# SWM330 register map
File version: 1.0
CPU: CM0 r1p0, little endian, 2 interrupt priority bits
Registers are 32-bit, read-write, no defined reset value unless marked. A register's access mark holds for its fields unless they carry their own. Offsets are from the block's base; [hi:lo] are bit positions; lines under a group give offsets from that group; {n}, {i} and the like mark numbered series; 'fields as' and 'values as' point back to an identical list.

## DMA2D — Registers group
Base 0x40003000
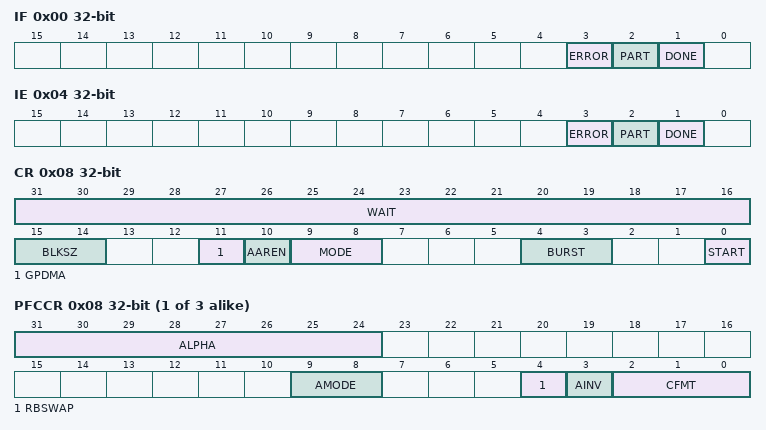
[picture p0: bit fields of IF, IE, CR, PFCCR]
0x00 IF
  [3] ERROR, [2] PART, [1] DONE
0x04 IE
  [3] ERROR, [2] PART, [1] DONE
0x08 CR
  [31:16] WAIT, [15:14] BLKSZ, [11] GPDMA, [10] AAREN, [9:8] MODE, [4:3] BURST, [0] START
{0x10+0x10*i} L{i} group (i=0..2) — register cluster
  0x00 MAR
  0x04 OR
  0x08 PFCCR
    [31:24] ALPHA, [9:8] AMODE, [4] RBSWAP, [3] AINV, [2:0] CFMT
  0x0C COLOR
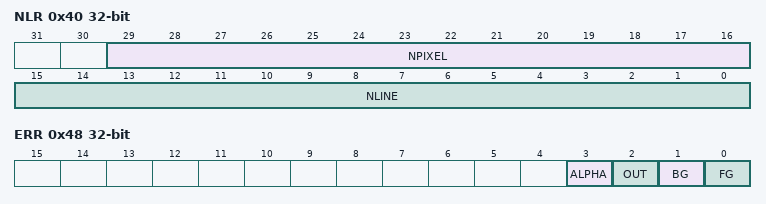
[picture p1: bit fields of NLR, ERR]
0x40 NLR
  [29:16] NPIXEL, [15:0] NLINE
0x44 AAR
0x48 ERR
  [3] ALPHA, [2] OUT, [1] BG, [0] FG

## JPEG — Registers group
Base 0x40004000
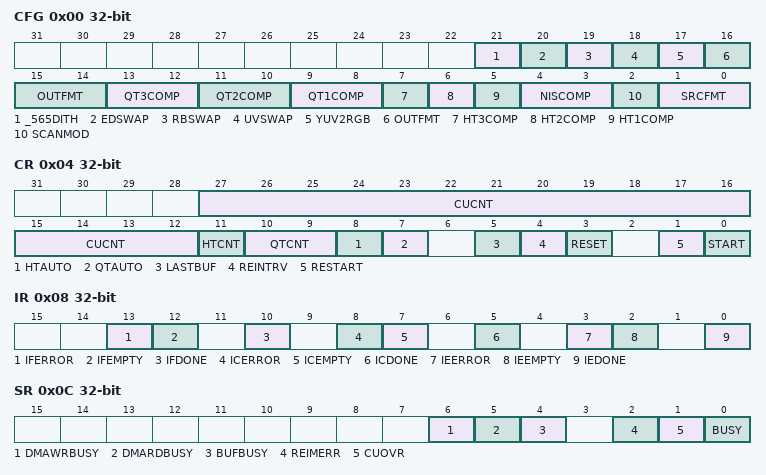
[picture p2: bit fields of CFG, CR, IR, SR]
0x00 CFG
  [21] _565DITH, [20] EDSWAP, [19] RBSWAP, [18] UVSWAP, [17] YUV2RGB, [16:14] OUTFMT, [13:12] QT3COMP, [11:10] QT2COMP, [9:8] QT1COMP, [7] HT3COMP, [6] HT2COMP, [5] HT1COMP, [4:3] NISCOMP, [2] SCANMOD, [1:0] SRCFMT
0x04 CR
  [27:12] CUCNT, [11] HTCNT, [10:9] QTCNT, [8] HTAUTO, [7] QTAUTO, [5] LASTBUF, [4] REINTRV, [3] RESET, [1] RESTART, [0] START
0x08 IR
  [13] IFERROR, [12] IFEMPTY, [10] IFDONE, [8] ICERROR, [7] ICEMPTY, [5] ICDONE, [3] IEERROR, [2] IEEMPTY, [0] IEDONE
0x0C SR
  [6] DMAWRBUSY, [5] DMARDBUSY, [4] BUFBUSY, [2] REIMERR, [1] CUOVR, [0] BUSY
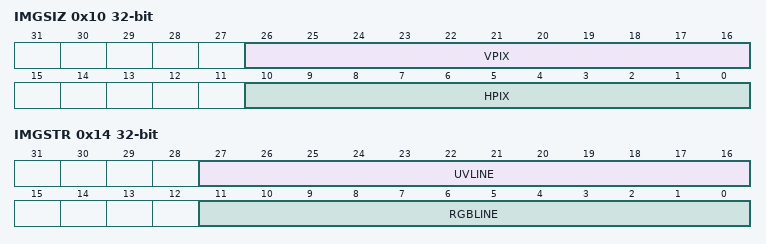
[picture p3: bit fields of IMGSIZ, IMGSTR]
0x10 IMGSIZ
  [26:16] VPIX, [10:0] HPIX
0x14 IMGSTR
  [27:16] UVLINE, [11:0] RGBLINE
0x18 CSBASE
0x1C YBASE
0x1C RGBASE (alternate view of YBASE)
0x20 UBASE
0x24 VBASE
0x28 QTBASE
0x2C HTBASE
0x30 CODLEN
{0x100+4i} QTABLE0_[{i}] (i=0..15) wo
{0x140+4i} QTABLE1_[{i}] (i=0..15) wo
{0x180+4i} QTABLE2_[{i}] (i=0..15) wo
0x200 HTABLE0 group — register cluster
  {0x0+4j} DC_CODEWORD[{j}] (j=0..5) wo
  {0x18+4j} DC_CODELEN[{j}] (j=0..1) wo
  {0x20+4j} DC_CODEVAL[{j}] (j=0..1) wo
  {0x28+4j} AC_CODEWORD[{j}] (j=0..7) wo
  {0x48+4j} AC_CODEADDR[{j}] (j=0..3) wo
  {0x58+4j} AC_CODEVAL[{j}] (j=0..40) wo
0x300 HTABLE1 group — register cluster
  {0x0+4j} DC_CODEWORD[{j}] (j=0..5) wo
  {0x18+4j} DC_CODELEN[{j}] (j=0..1) wo
  {0x20+4j} DC_CODEVAL[{j}] (j=0..1) wo
  {0x28+4j} AC_CODEWORD[{j}] (j=0..7) wo
  {0x48+4j} AC_CODEADDR[{j}] (j=0..3) wo
  {0x58+4j} AC_CODEVAL[{j}] (j=0..40) wo

## SRA — Registers group
Base 0x40002800
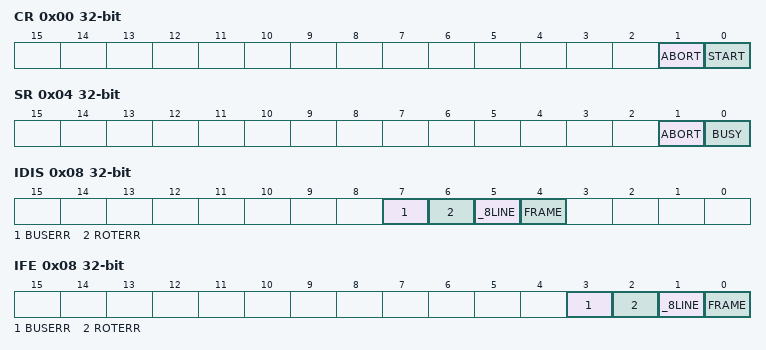
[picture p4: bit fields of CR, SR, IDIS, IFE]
0x00 CR wo
  [1] ABORT, [0] START
0x04 SR ro
  [1] ABORT, [0] BUSY
0x08 IDIS
  [7] BUSERR, [6] ROTERR, [5] _8LINE, [4] FRAME
0x08 IFE (alternate view of IDIS)
  [3] BUSERR, [2] ROTERR, [1] _8LINE, [0] FRAME
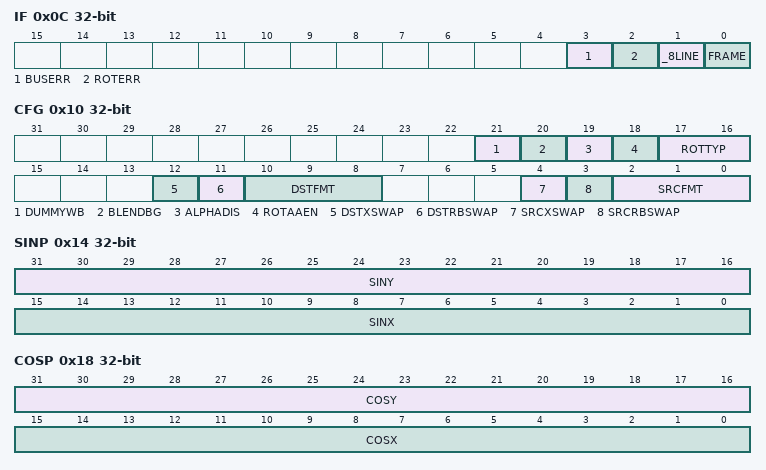
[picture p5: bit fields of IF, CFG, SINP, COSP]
0x0C IF
  [3] BUSERR, [2] ROTERR, [1] _8LINE, [0] FRAME
0x10 CFG
  [21] DUMMYWB, [20] BLENDBG, [19] ALPHADIS, [18] ROTAAEN, [17:16] ROTTYP, [12] DSTXSWAP, [11] DSTRBSWAP, [10:8] DSTFMT, [4] SRCXSWAP, [3] SRCRBSWAP, [2:0] SRCFMT
0x14 SINP
  [31:16] SINY, [15:0] SINX
0x18 COSP
  [31:16] COSY, [15:0] COSX
0x1C SRC_TILE_POSX
0x20 SRC_TILE_POSY
0x24 DST_TILE_OFFX
0x28 DST_TILE_OFFY
0x2C BGCOLOR
0x30 SRCBASE
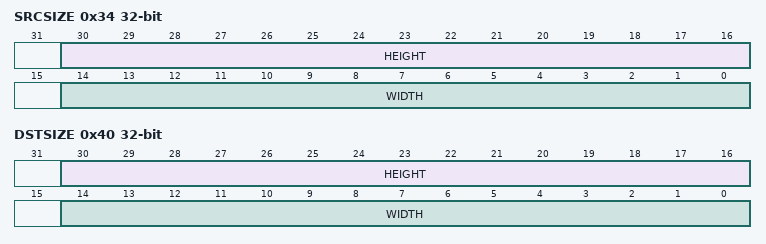
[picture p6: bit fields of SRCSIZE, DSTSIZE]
0x34 SRCSIZE
  [30:16] HEIGHT, [14:0] WIDTH
0x38 SRCSTRIDE
0x3C DSTBASE
0x40 DSTSIZE
  [30:16] HEIGHT, [14:0] WIDTH
0x44 DSTSTRIDE

## DVP — Registers group
Base 0x40003900
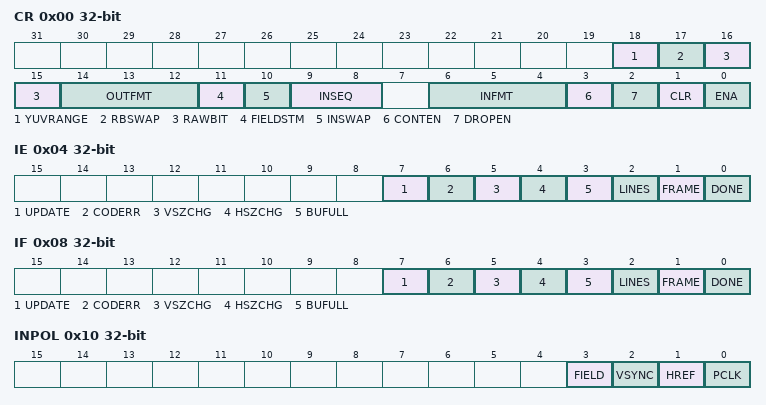
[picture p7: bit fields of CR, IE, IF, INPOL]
0x00 CR
  [18] YUVRANGE, [17] RBSWAP, [16:15] RAWBIT, [14:12] OUTFMT, [11] FIELDSTM, [10] INSWAP, [9:8] INSEQ, [6:4] INFMT, [3] CONTEN, [2] DROPEN, [1] CLR, [0] ENA
0x04 IE
  [7] UPDATE, [6] CODERR, [5] VSZCHG, [4] HSZCHG, [3] BUFULL, [2] LINES, [1] FRAME, [0] DONE
0x08 IF
  fields as IE
0x0C ICFG
  [30:16] LINES
0x10 INPOL
  [3] FIELD, [2] VSYNC, [1] HREF, [0] PCLK
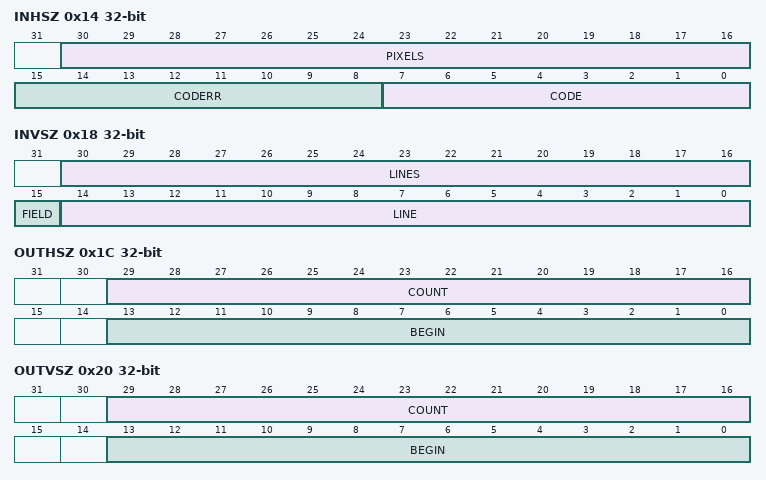
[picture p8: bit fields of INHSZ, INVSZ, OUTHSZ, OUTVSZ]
0x14 INHSZ ro
  [30:16] PIXELS, [15:8] CODERR, [7:0] CODE
0x18 INVSZ ro
  [30:16] LINES, [15] FIELD, [14:0] LINE
0x1C OUTHSZ
  [29:16] COUNT, [13:0] BEGIN
0x20 OUTVSZ
  [29:16] COUNT, [13:0] BEGIN
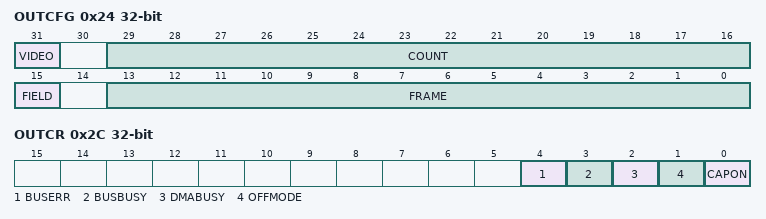
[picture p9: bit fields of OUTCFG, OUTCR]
0x24 OUTCFG
  [31] VIDEO, [29:16] COUNT, [15] FIELD, [13:0] FRAME
0x28 CURFRM ro
0x2C OUTCR
  [4] BUSERR, [3] BUSBUSY, [2] DMABUSY, [1] OFFMODE, [0] CAPON
0x30 UPDATE
0x34 BASE_YRAW
0x38 BASE_UV
0x3C ADDR_YRAW ro
0x40 ADDR_UV ro
0x44 STEP_YRAW
0x48 STEP_UV
0x4C BASE_YRAW_SHA ro
0x50 BASE_UV_SHA ro
0x54 STEP_SHA ro

## FMC — Registers group
Base 0x40045800
0x00 DATA
0x04 ADDR
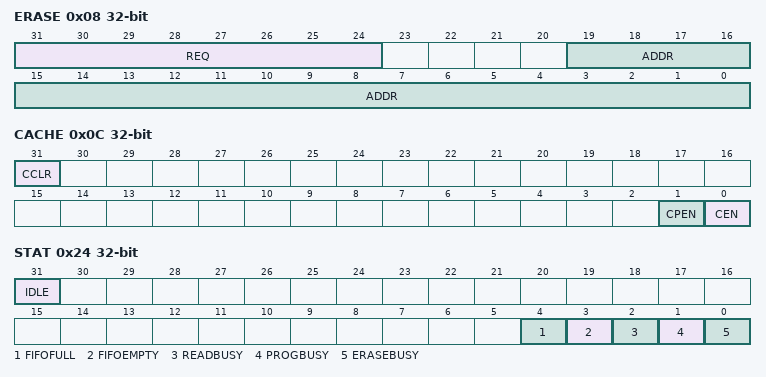
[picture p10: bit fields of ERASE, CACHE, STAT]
0x08 ERASE
  [31:24] REQ, [19:0] ADDR
0x0C CACHE
  [31] CCLR, [1] CPEN, [0] CEN
0x10 CFG0
  [9] WREN
{0x10+4i} CFG{i} (i=1..4)
0x24 STAT
  [31] IDLE, [4] FIFOFULL, [3] FIFOEMPTY, [2] READBUSY, [1] PROGBUSY, [0] ERASEBUSY

## CRC — Registers group
Base 0x40002000
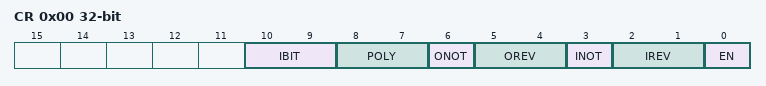
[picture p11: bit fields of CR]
0x00 CR
  [10:9] IBIT, [8:7] POLY, [6] ONOT, [5:4] OREV, [3] INOT, [2:1] IREV, [0] EN
0x04 DATAIN wo
0x08 INIVAL
0x0C RESULT ro

## RTC — Registers group
Base 0x400A3800
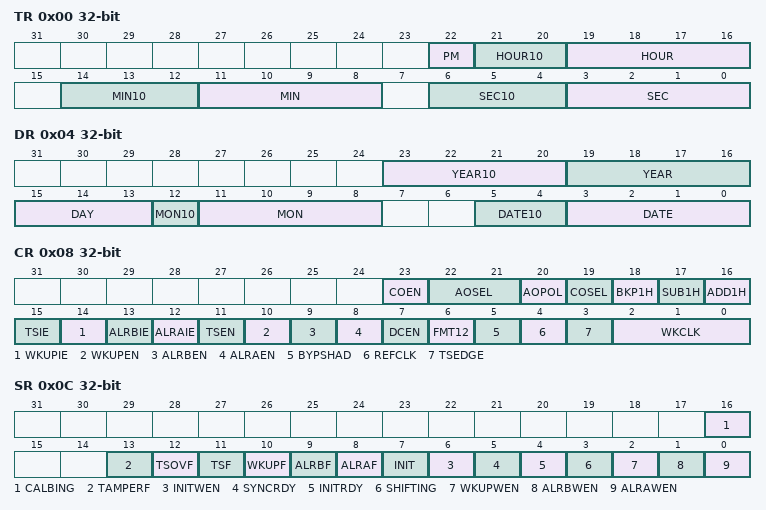
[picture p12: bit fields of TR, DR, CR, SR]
0x00 TR
  [22] PM, [21:20] HOUR10, [19:16] HOUR, [14:12] MIN10, [11:8] MIN, [6:4] SEC10, [3:0] SEC
0x04 DR
  [23:20] YEAR10, [19:16] YEAR, [15:13] DAY, [12] MON10, [11:8] MON, [5:4] DATE10, [3:0] DATE
0x08 CR
  [23] COEN, [22:21] AOSEL, [20] AOPOL, [19] COSEL, [18] BKP1H, [17] SUB1H, [16] ADD1H, [15] TSIE, [14] WKUPIE, [13] ALRBIE, [12] ALRAIE, [11] TSEN, [10] WKUPEN, [9] ALRBEN, [8] ALRAEN, [7] DCEN, [6] FMT12, [5] BYPSHAD, [4] REFCLK, [3] TSEDGE, [2:0] WKCLK
0x0C SR
  [16] CALBING, [13] TAMPERF, [12] TSOVF, [11] TSF, [10] WKUPF, [9] ALRBF, [8] ALRAF, [7] INIT, [6] INITWEN, [5] SYNCRDY, [4] INITRDY, [3] SHIFTING, [2] WKUPWEN, [1] ALRBWEN, [0] ALRAWEN
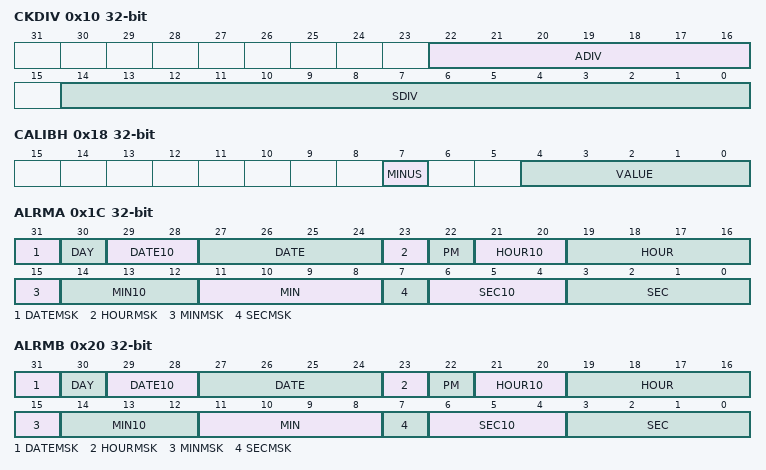
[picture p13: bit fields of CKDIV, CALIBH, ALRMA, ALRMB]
0x10 CKDIV
  [22:16] ADIV, [14:0] SDIV
0x14 WKTIM
0x18 CALIBH
  [7] MINUS, [4:0] VALUE
0x1C ALRMA
  [31] DATEMSK, [30] DAY, [29:28] DATE10, [27:24] DATE, [23] HOURMSK, [22] PM, [21:20] HOUR10, [19:16] HOUR, [15] MINMSK, [14:12] MIN10, [11:8] MIN, [7] SECMSK, [6:4] SEC10, [3:0] SEC
0x20 ALRMB
  fields as ALRMA
0x24 UNLOCK
0x28 SUBSEC ro
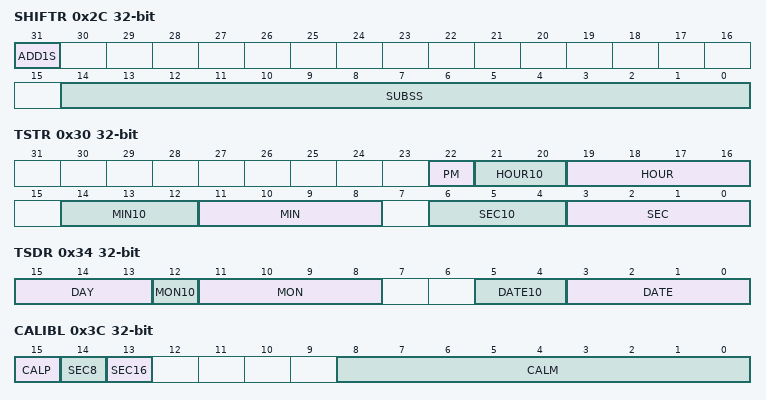
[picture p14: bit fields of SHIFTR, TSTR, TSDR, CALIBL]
0x2C SHIFTR
  [31] ADD1S, [14:0] SUBSS
0x30 TSTR ro
  fields as TR
0x34 TSDR ro
  [15:13] DAY, [12] MON10, [11:8] MON, [5:4] DATE10, [3:0] DATE
0x38 TSSS ro
0x3C CALIBL
  [15] CALP, [14] SEC8, [13] SEC16, [8:0] CALM
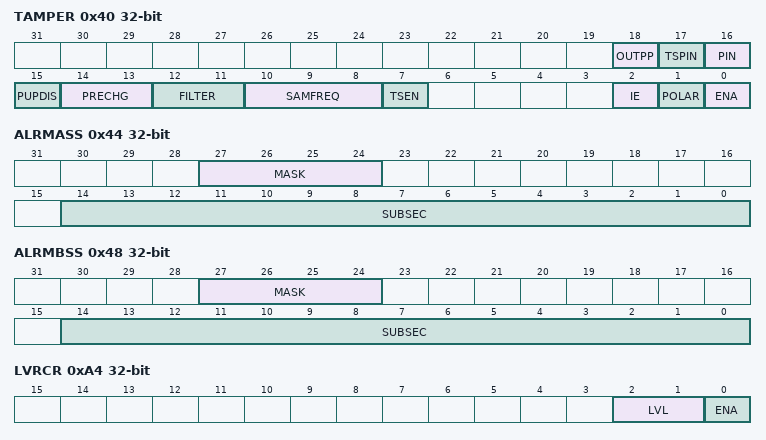
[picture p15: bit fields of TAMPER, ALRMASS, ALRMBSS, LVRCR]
0x40 TAMPER
  [18] OUTPP, [17] TSPIN, [16] PIN, [15] PUPDIS, [14:13] PRECHG, [12:11] FILTER, [10:8] SAMFREQ, [7] TSEN, [2] IE, [1] POLAR, [0] ENA
0x44 ALRMASS
  [27:24] MASK, [14:0] SUBSEC
0x48 ALRMBSS
  [27:24] MASK, [14:0] SUBSEC
{0x50+4i} BACKUP[{i}] (i=0..19)
0xA4 LVRCR
  [2:1] LVL, [0] ENA
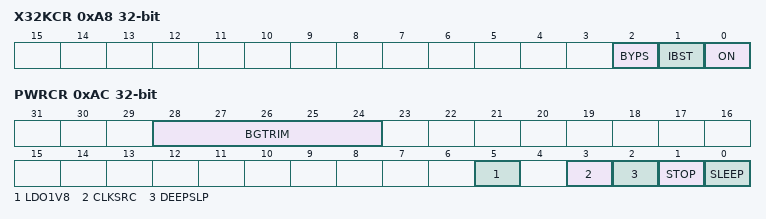
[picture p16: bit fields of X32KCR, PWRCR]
0xA8 X32KCR
  [2] BYPS, [1] IBST, [0] ON
0xAC PWRCR
  [28:24] BGTRIM, [5] LDO1V8, [3] CLKSRC, [2] DEEPSLP, [1] STOP, [0] SLEEP

## WDT — Registers group
Base 0x400A0800
0x00 RSTVAL
0x04 INTVAL
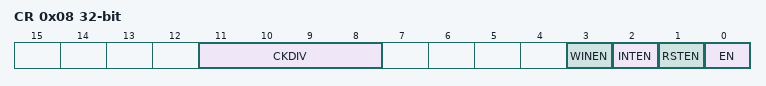
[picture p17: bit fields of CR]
0x08 CR
  [11:8] CKDIV, [3] WINEN, [2] INTEN, [1] RSTEN, [0] EN
0x0C IF
0x10 FEED
